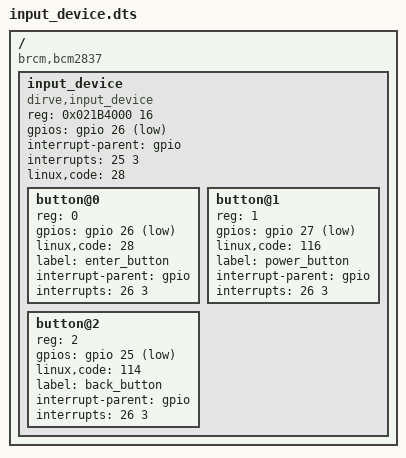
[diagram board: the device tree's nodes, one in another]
/{
    input_device {
        compatible = "dirve,input_device";
        reg = <0x021B4000 16>;// 设备树里面指定 寄存器 基地址; 0x021B4000 是寄存器基地址，16是寄存器长度
        // 指定中断号  属于哪个gpio， 上升下降沿都会触发； 指定用哪个中断，并且指定中断触发 类型
		gpios = <&gpio 25  GPIO_ACTIVE_LOW｜GPIO_ACTIVE_HEIGH >;// 上升下降沿都会触发；
		interrupt-parent = <&gpio>;
		interrupts = <25 3>;
    }


    input_device {
        compatible = "dirve,input_device";
        gpios = <&gpio 25 1>; /* GPIO26，active-low */
        linux,code = <28>; /* KEY_ENTER */
		interrupt-parent = <&gpio>;
		interrupts = <25 3>;
    };

} 








这种写法 不知道如何使用，应该是单独放在 一个 文件里

/dts-v1/;
/plugin/;

/ {
    compatible = "brcm,bcm2837";

    fragment@0 {
        target-path = "/";
        __overlay__ {
            input_device {
                compatible = "dirve,input_device";
                gpios = <&gpio 26 1>; /* GPIO26，active-low */
                linux,code = <28>; /* KEY_ENTER */
            };
        };
    };
};




/dts-v1/;
/plugin/;

/ {
    compatible = "brcm,bcm2837";

    fragment@0 {
        target-path = "/";
        __overlay__ {
            input_device {
                compatible = "dirve,input_device";
                #address-cells = <1>;
                #size-cells = <0>;

                /* 按键 1：GPIO26 */
                button@0 {
                    reg = <0>; /* 子节点标识 */
                    gpios = <&gpio 26 1>; /* GPIO26, active-low */
                    linux,code = <28>; /* KEY_ENTER */
                    label = "enter_button";
                    interrupt-parent = <&gpio>;
                    interrupts = <26 3>;
                };

                /* 按键 2：GPIO27 */
                button@1 {
                    reg = <1>;
                    gpios = <&gpio 27 1>; /* GPIO27, active-low */
                    linux,code = <116>; /* KEY_POWER */
                    label = "power_button";
                    interrupt-parent = <&gpio>;
                    interrupts = <26 3>;
                };

                /* 按键 3：GPIO25 */
                button@2 {
                    reg = <2>;
                    gpios = <&gpio 25 1>; /* GPIO25, active-low */
                    linux,code = <114>; /* KEY_BACK */
                    label = "back_button";
                    interrupt-parent = <&gpio>;
                    interrupts = <26 3>;
                };
            };
        };
    };
};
